# STM32WBAxx register map
File version: 0.1
Registers are 32-bit, read-write, reset 0x0 unless marked. A register's access mark holds for its fields unless they carry their own. Offsets are from the block's base; [hi:lo] are bit positions; {n}, {i} and the like mark numbered series.

## GPIOI — General-purpose I/Os
Base 0x42022000
Same registers: SEC_GPIOI 0x52022000
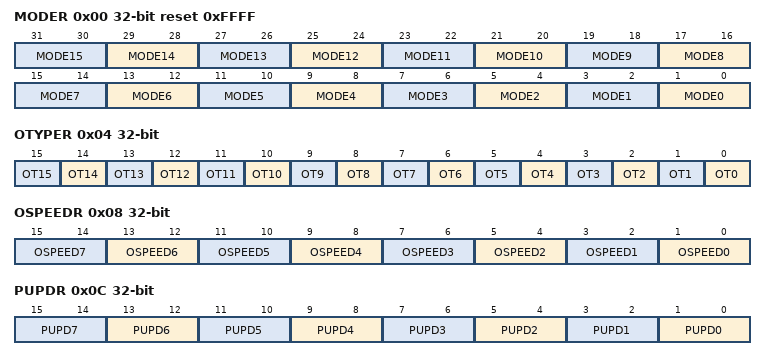
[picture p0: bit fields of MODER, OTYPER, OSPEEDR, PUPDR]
0x00 MODER reset 0xFFFF — GPIO port mode register
  [2n+1:2n] MODE{n} (n=0..15) — Port x configuration bits (y = 0..15)
0x04 OTYPER — GPIO port output type register
  [n] OT{n} (n=0..15) — Port x configuration bits (y = 0..15)
0x08 OSPEEDR — GPIO port output speed register
  [2n+1:2n] OSPEED{n} (n=0..7) — Port x configuration bits (y =7 .. 0)
0x0C PUPDR — GPIO port pull-up/pull-down register
  [2n+1:2n] PUPD{n} (n=0..7) — Port x configuration bits (y =7 .. 0)
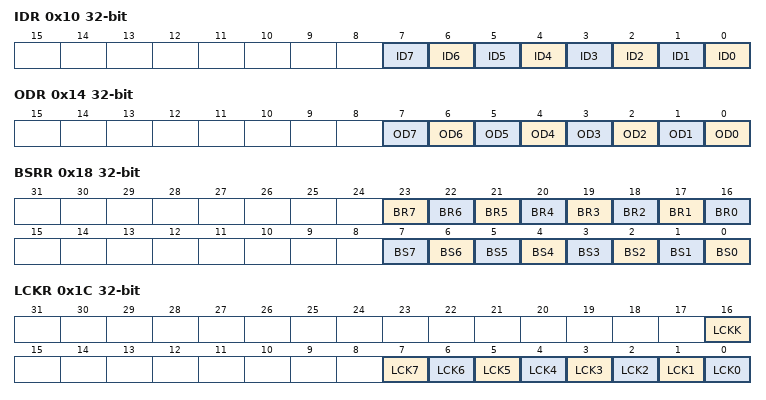
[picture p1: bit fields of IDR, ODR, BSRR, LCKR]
0x10 IDR ro — GPIO port input data register
  [n] ID{n} (n=0..7) — Port input data (y = 0..7)
0x14 ODR — GPIO port output data register
  [n] OD{n} (n=0..7) — Port output data (y = 0..7)
0x18 BSRR wo — GPIO port bit set/reset register
  [n+16] BR{n} (n=1..7) — Port x reset bit y (y = 0..7)
  [16] BR0 — Port x set bit y (y= 0..7)
  [n] BS{n} (n=0..7) — Port x set bit y (y= 0..7)
0x1C LCKR — GPIO port configuration lock register
  [16] LCKK — Lock key
  [n] LCK{n} (n=0..7) — Port x lock bit y (y= 0..15)
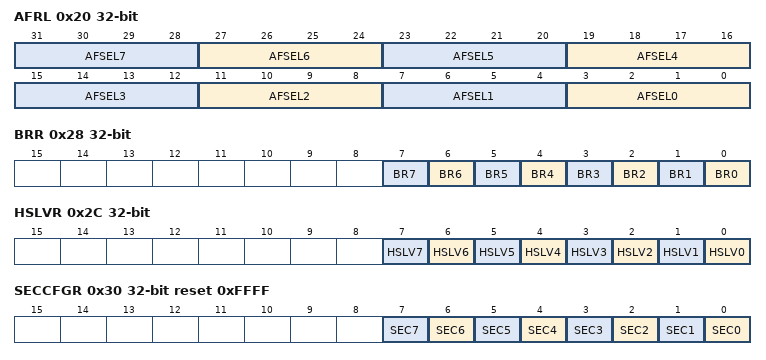
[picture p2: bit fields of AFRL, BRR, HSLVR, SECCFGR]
0x20 AFRL — GPIO alternate function low register
  [4n+3:4n] AFSEL{n} (n=0..7) — Alternate function selection for port x bit y (y = 0..7)
0x28 BRR wo — GPIO port bit reset register
  [n] BR{n} (n=0..7) — Port x reset IO pin y
0x2C HSLVR — GPIO high-speed low-voltage register
  [n] HSLV{n} (n=0..7) — Port x high-speed low-voltage configuration (y= 7 to 0)
0x30 SECCFGR wo reset 0xFFFF — GPIO secure configuration register
  [n] SEC{n} (n=0..7) — I/O pin of Port x secure bit enable

## ICache
Base 0x40030400
Same registers: SEC_ICache 0x50030400
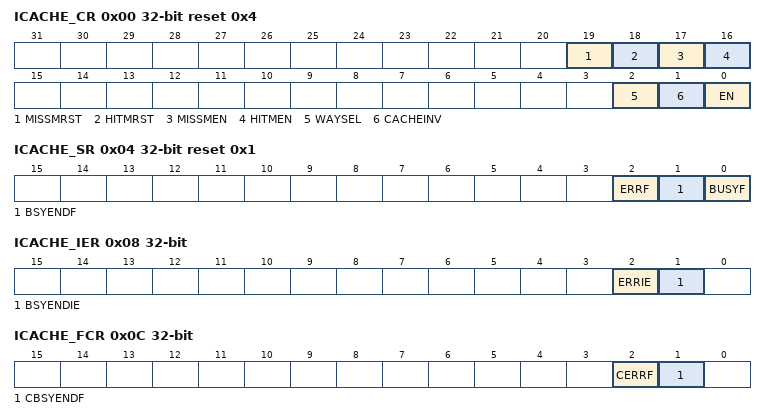
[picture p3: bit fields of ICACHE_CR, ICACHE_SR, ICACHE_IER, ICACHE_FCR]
0x00 ICACHE_CR access per field reset 0x4 — ICACHE control register
  [19] MISSMRST rw, [18] HITMRST rw, [17] MISSMEN rw, [16] HITMEN rw, [2] WAYSEL rw, [1] CACHEINV wo, [0] EN rw
0x04 ICACHE_SR ro reset 0x1 — ICACHE status register
  [2] ERRF, [1] BSYENDF, [0] BUSYF
0x08 ICACHE_IER — ICACHE interrupt enable register
  [2] ERRIE, [1] BSYENDIE
0x0C ICACHE_FCR wo — ICACHE flag clear register
  [2] CERRF, [1] CBSYENDF
0x10 ICACHE_HMONR ro — ICACHE hit monitor register
  [31:0] HITMON
0x14 ICACHE_MMONR ro — ICACHE miss monitor register
  [15:0] MISSMON
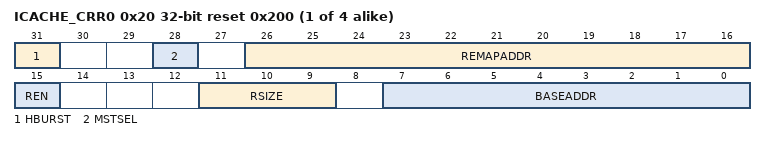
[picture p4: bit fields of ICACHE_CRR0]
{0x20+4i} ICACHE_CRR{i} reset 0x200 (i=0..3) — ICACHE region configuration register
  [31] HBURST, [28] MSTSEL, [26:16] REMAPADDR, [15] REN, [11:9] RSIZE, [7:0] BASEADDR

## DCACHE
Base 0x40031400
Same registers: SEC_DCACHE 0x50031400
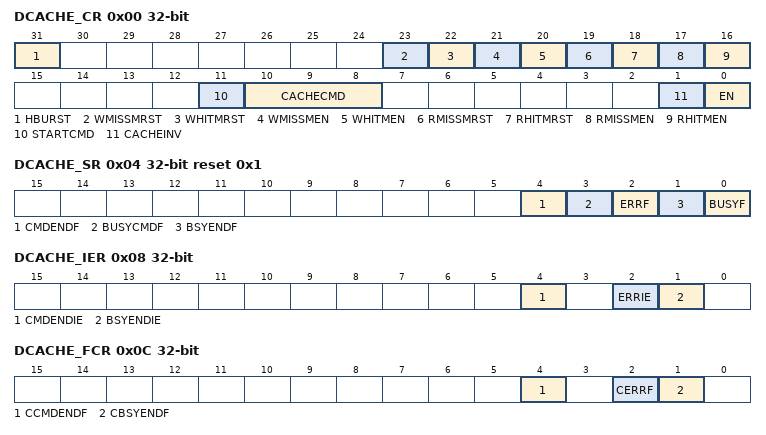
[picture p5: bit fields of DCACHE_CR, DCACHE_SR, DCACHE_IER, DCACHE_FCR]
0x00 DCACHE_CR access per field — DCACHE control register
  [31] HBURST rw, [23] WMISSMRST rw, [22] WHITMRST rw, [21] WMISSMEN rw, [20] WHITMEN rw, [19] RMISSMRST rw, [18] RHITMRST rw, [17] RMISSMEN rw, [16] RHITMEN rw, [11] STARTCMD wo, [10:8] CACHECMD rw, [1] CACHEINV wo, [0] EN rw
0x04 DCACHE_SR ro reset 0x1 — DCACHE status register
  [4] CMDENDF, [3] BUSYCMDF, [2] ERRF, [1] BSYENDF, [0] BUSYF
0x08 DCACHE_IER — DCACHE interrupt enable register
  [4] CMDENDIE, [2] ERRIE, [1] BSYENDIE
0x0C DCACHE_FCR wo — DCACHE flag clear register
  [4] CCMDENDF, [2] CERRF, [1] CBSYENDF
0x10 DCACHE_RHMONR ro — DCACHE read-hit monitor register
  [31:0] RHITMON
0x14 DCACHE_RMMONR ro — DCACHE read-miss monitor register
  [15:0] MRISSMON — RMISSMON
0x20 DCACHE_WHMONR ro — write-hit monitor register
  [31:0] WHITMON
0x24 DCACHE_WMMONR ro — write-miss monitor register
  [15:0] WMISSMON
0x28 DCACHE_CMDRSADDRR — command range start address register
  [31:0] CMDSTARTADDR
0x2C DCACHE_CMDREADDRR — command range start address register
  [31:0] CMDENDADDR

## IWDG — Independent watchdog
Base 0x40003000
Same registers: SEC_IWDG 0x50003000
0x00 KR wo — Key register
  [15:0] KEY — Key value (write only, read 0x0000)
0x04 PR — Prescaler register
  [3:0] PR — Prescaler divider
0x08 RLR reset 0xFFF — Reload register
  [11:0] RL — Watchdog counter reload value
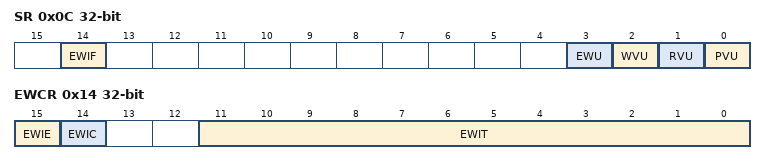
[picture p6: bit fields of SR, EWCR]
0x0C SR ro — Status register
  [14] EWIF — Watchdog Early interrupt flag
  [3] EWU — Watchdog interrupt comparator value update
  [2] WVU — Watchdog counter window value update
  [1] RVU — Watchdog counter reload value update
  [0] PVU — Watchdog prescaler value update
0x10 WINR reset 0xFFF — Window register
  [11:0] WIN — Watchdog counter window value
0x14 EWCR — IWDG early wakeup interrupt register
  [15] EWIE — Watchdog early interrupt enable
  [14] EWIC — Watchdog early interrupt acknowledge
  [11:0] EWIT — Watchdog counter window value
